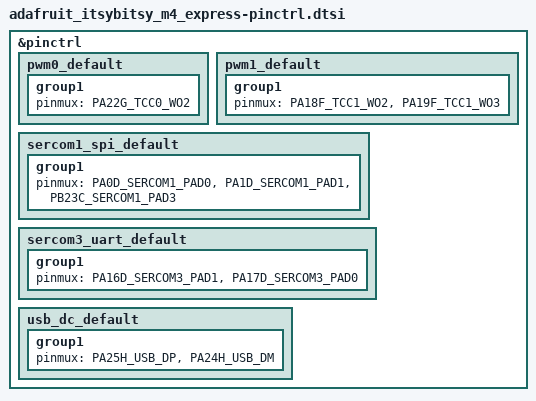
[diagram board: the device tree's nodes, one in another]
/*
 * Copyright (c) 2022, Gerson Fernando Budke <nandojve@gmail.com>
 * SPDX-License-Identifier: Apache-2.0
 */

#include <dt-bindings/pinctrl/same51g-pinctrl.h>

&pinctrl {
	pwm0_default: pwm0_default {
		group1 {
			pinmux = <PA22G_TCC0_WO2>;
		};
	};
	pwm1_default: pwm1_default {
		group1 {
			pinmux = <PA18F_TCC1_WO2>,
				 <PA19F_TCC1_WO3>;
		};
	};

	sercom1_spi_default: sercom1_spi_default {
		group1 {
			pinmux = <PA0D_SERCOM1_PAD0>,
				 <PA1D_SERCOM1_PAD1>,
				 <PB23C_SERCOM1_PAD3>;
		};
	};

	sercom3_uart_default: sercom3_uart_default {
		group1 {
			pinmux = <PA16D_SERCOM3_PAD1>,
				 <PA17D_SERCOM3_PAD0>;
		};
	};

	usb_dc_default: usb_dc_default {
		group1 {
			pinmux = <PA25H_USB_DP>,
				 <PA24H_USB_DM>;
		};
	};
};
